# RX64M_CAC_Pilot register map
File version: 1.0
RX64M_CAC_Pilot peripheral registers generated from iodefine.h (pilot).
Registers are 8-bit, read-write, reset 0x0 unless marked. A register's access mark holds for its fields unless they carry their own. Offsets are from the block's base; lines under a group give offsets from that group; [hi:lo] are bit positions; {n}, {i} and the like mark numbered series; 'fields as' and 'values as' point back to an identical list; <NAME> marks a mode.

## Memory map
0x0008B000 CAC size 0xC

## CAC
Base 0x0008B000
0x00 CACR0
  [0] CFME
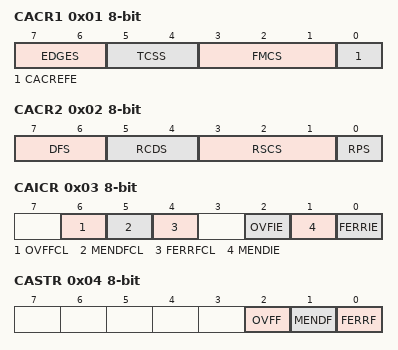
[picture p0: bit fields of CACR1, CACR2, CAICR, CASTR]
0x01 CACR1
  [7:6] EDGES, [5:4] TCSS, [3:1] FMCS, [0] CACREFE
0x02 CACR2
  [7:6] DFS, [5:4] RCDS, [3:1] RSCS, [0] RPS
0x03 CAICR
  [6] OVFFCL, [5] MENDFCL, [4] FERRFCL, [2] OVFIE, [1] MENDIE, [0] FERRIE
0x04 CASTR
  [2] OVFF, [1] MENDF, [0] FERRF
0x06 CAULVR 16-bit
0x08 CALLVR 16-bit
0x0A CACNTBR 16-bit ro
